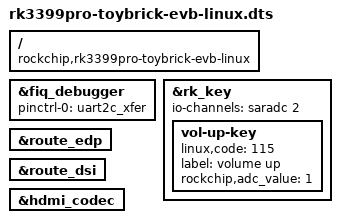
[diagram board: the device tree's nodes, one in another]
/dts-v1/;
#include "rk3399pro-toybrick-evb.dtsi"
#include "rk3399-android.dtsi"

/* Default camera: ov9750 */
#include "rk3399pro-toybrick-ov9750.dtsi"

/ {
	compatible = "rockchip,rk3399pro-toybrick-evb-linux","rockchip,rk3399pro";
};

&fiq_debugger {
	pinctrl-0 = <&uart2c_xfer>;
};

&rk_key {
	status = "okay";

	io-channels = <&saradc 2>;

	vol-up-key {
		linux,code = <115>;
		label = "volume up";
		rockchip,adc_value = <1>;
	};
};

&route_edp {
	status = "okay";
};

&route_dsi {
	status = "okay";
};

&hdmi_codec {
	status = "okay";
};
